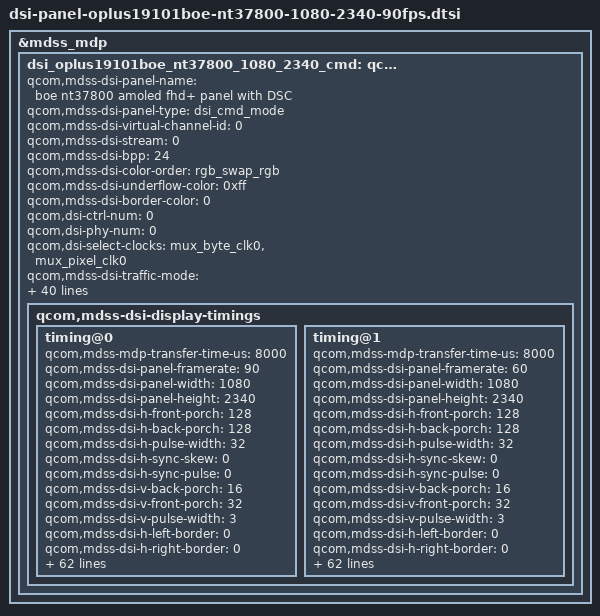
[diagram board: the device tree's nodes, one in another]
&mdss_mdp {
	dsi_oplus19101boe_nt37800_1080_2340_cmd: qcom,mdss_dsi_oplus19101boe_nt37800_1080_2340_cmd {
		qcom,mdss-dsi-panel-name =
		  "boe nt37800 amoled fhd+ panel with DSC";
		qcom,mdss-dsi-panel-type = "dsi_cmd_mode";
		qcom,mdss-dsi-virtual-channel-id = <0>;
		qcom,mdss-dsi-stream = <0>;
		qcom,mdss-dsi-bpp = <24>;
		qcom,mdss-dsi-color-order = "rgb_swap_rgb";
		qcom,mdss-dsi-underflow-color = <0xff>;
		qcom,mdss-dsi-border-color = <0>;

		qcom,dsi-ctrl-num = <0>;
		qcom,dsi-phy-num = <0>;
		qcom,dsi-select-clocks = "src_byte_clk0", "src_pixel_clk0";

		qcom,mdss-dsi-traffic-mode = "non_burst_sync_event";
		qcom,mdss-dsi-lane-map = "lane_map_0123";
		qcom,mdss-dsi-bllp-eof-power-mode;
		qcom,mdss-dsi-bllp-power-mode;
		qcom,mdss-dsi-lane-0-state;
		qcom,mdss-dsi-lane-1-state;
		qcom,mdss-dsi-lane-2-state;
		qcom,mdss-dsi-lane-3-state;
		qcom,mdss-dsi-dma-trigger = "trigger_sw";
		qcom,mdss-dsi-mdp-trigger = "none";
		qcom,mdss-dsi-reset-sequence = <1 10>, <0 10>, <1 10>;
		qcom,mdss-dsi-te-pin-select = <1>;
		qcom,mdss-dsi-wr-mem-start = <0x2c>;
		qcom,mdss-dsi-wr-mem-continue = <0x3c>;
		qcom,mdss-dsi-te-dcs-command = <1>;
		qcom,mdss-dsi-te-check-enable;
		qcom,mdss-dsi-te-using-te-pin;
		qcom,mdss-dsi-lp11-init;
		qcom,mdss-dsi-panel-hdr-enabled;
		qcom,mdss-dsi-panel-hdr-color-primaries = <15000 15500 34000
			16000 13250 34500 7500 3000>;
		qcom,mdss-dsi-panel-peak-brightness = <4300000>;
		qcom,mdss-dsi-panel-blackness-level = <1023>;
		qcom,mdss-brightness-max-level = <1023>;

		qcom,mdss-dsi-display-timings {
			timing@0{
				//qcom,mdss-dsi-panel-clockrate = <1107000000>;
				qcom,mdss-mdp-transfer-time-us = <8000>;
				qcom,mdss-dsi-panel-framerate = <90>; /* 90 FPS */
				qcom,mdss-dsi-panel-width = <1080>;
				qcom,mdss-dsi-panel-height = <2340>;
				qcom,mdss-dsi-h-front-porch = <128>;
				qcom,mdss-dsi-h-back-porch = <128>;
				qcom,mdss-dsi-h-pulse-width = <32>;
				qcom,mdss-dsi-h-sync-skew = <0>;
				qcom,mdss-dsi-h-sync-pulse = <0>;
				qcom,mdss-dsi-v-back-porch = <16>;
				qcom,mdss-dsi-v-front-porch = <32>;
				qcom,mdss-dsi-v-pulse-width = <3>;
				qcom,mdss-dsi-h-left-border = <0>;
				qcom,mdss-dsi-h-right-border = <0>;
				qcom,mdss-dsi-v-top-border = <0>;
				qcom,mdss-dsi-v-bottom-border = <0>;
				qcom,mdss-dsi-panel-jitter = <0xa 0x1>;
				qcom,mdss-dsi-timing-switch-command = [
					39 01 00 00 00 00 06 F0 55 AA 52 08 00
					15 01 00 00 00 00 02 6F 0E
					15 01 00 00 00 00 02 BA 08
					15 01 00 00 00 00 02 6F 03
					39 01 00 00 00 00 04 C0 80 00 00
				];
				qcom,mdss-dsi-on-command = [
					39 01 00 00 00 00 06 F0 55 AA 52 00 00
					/* 90 FPS Setting */
					39 01 00 00 00 00 06 F0 55 AA 52 08 00 /* 90 FPS */
					15 01 00 00 00 00 02 6F 0E
					15 01 00 00 00 00 02 BA 08
					15 01 00 00 00 00 02 6F 03
					39 01 00 00 00 00 04 C0 80 00 00 /* 90 FPS */
					05 01 00 00 00 00 01 35
					39 01 00 00 00 00 05 3B 00 10 00 04
					15 01 00 00 00 00 02 53 20
					39 01 00 00 00 00 05 51 03 FF 0F FF
					39 01 00 00 00 00 05 2A 00 00 04 37
					39 01 00 00 00 00 05 2B 00 00 09 23
					/* DSC Setting */
					39 01 00 00 00 00 13 93 89 28 00 14 02 00 02 0E 01 E8 00 07 05 0E 05 16 10 F0
					15 01 00 00 00 00 02 90 01
					15 01 00 00 00 00 02 03 11
					05 01 00 00 00 00 01 2C
					/* Sleep Out(11h) */
					05 01 00 00 78 00 01 11
					];
				qcom,mdss-dsi-post-on-backlight = [
					05 01 00 00 00 00 01 29
					];
				qcom,mdss-dsi-off-command = [
					05 01 00 00 0A 00 01 28
					05 01 00 00 78 00 01 10];
				qcom,mdss-dsi-lp1-command = [    /* AOD ON */
					05 01 00 00 00 00 01 39
					15 01 00 00 00 00 02 65 01
					05 01 00 00 00 00 01 2C
					];
				qcom,mdss-dsi-nolp-command = [    /* AOD OFF */
					15 01 00 00 00 00 02 65 00
					05 01 00 00 00 00 01 38
					05 01 00 00 00 00 01 2C
					];
				qcom,mdss-dsi-aod-hbm-on-command = [  /*AOD->HBM ON PANEL FINGERPRINT OFF*/
					39 01 00 00 00 00 03 F0 5A 5A
					39 01 00 00 00 00 03 51 03 FF
					15 01 00 00 00 00 02 53 E0
					/* HBM 670 ON */
					39 01 00 00 00 00 03 BD 00 00
					39 01 00 00 00 00 03 F0 A5 A5];
				qcom,mdss-dsi-aod-hbm-off-command = [  /*AOD->HBM OFF PANEL FINGERPRINT OFF*/
					39 01 00 00 00 00 03 F0 5A 5A
					39 01 00 00 00 00 03 BD 00 02
					39 01 00 00 00 00 03 F0 A5 A5
					39 01 00 00 00 00 03 51 00 01
					15 01 00 00 00 00 02 53 22];
				qcom,mdss-dsi-hbm-on-command = [
					39 01 00 00 00 00 03 51 0F FF
					];
				qcom,mdss-dsi-hbm-off-command = [
					39 01 00 00 00 00 03 51 06 40
					];
				qcom,mdss-dsi-normal-hbm-on-command = [
					39 01 00 00 00 00 03 51 0F FF
					];
				qcom,mdss-dsi-aod-high-mode-command = [
					/* AOD 50nit */
					39 01 00 00 00 00 03 F0 5A 5A
					15 01 00 00 00 00 02 53 22
					15 01 00 00 00 00 02 B0 A5
					15 01 00 00 00 00 02 C7 00
					39 01 00 00 00 00 03 F0 A5 A5];
				qcom,mdss-dsi-aod-low-mode-command = [
					/* AOD 10nit */
					39 01 00 00 00 00 03 F0 5A 5A
					15 01 00 00 00 00 02 53 23
					15 01 00 00 00 00 02 B0 A5
					15 01 00 00 00 00 02 C7 00
					39 01 00 00 00 00 03 F0 A5 A5];
				qcom,mdss-dsi-seed-1-command = [
					];
				qcom,mdss-dsi-seed-2-command = [
					];
				qcom,mdss-dsi-spr-0-command = [
					39 01 00 00 00 00 06 F0 55 AA 52 08 07
					39 01 00 00 00 00 07 B0 A4 40 70 60 00 00
					39 01 00 00 00 00 18 B1 08 18 00 18 08 00 00 00 00 00 00 00 00 00 00 00 00 00 00 00 00 00 00
					39 01 00 00 00 00 B5 B2 20 20 20 20 20 20 20 20 20 20 20 20 20 20 20 20 20 20 20 20 20 20 20 20 20 20 20 20 20 20 20 20 20 20 20 20 20 20 20 20 20 20 20 20 20 20 20 20 20 20 20 20 20 20 32 32 32 32 32 32 32 32 32 00 00 00 00 00 00 00 00 00 32 32 32 32 32 32 32 32 32 00 00 00 00 00 00 00 00 00 32 32 32 32 32 32 32 32 32 00 00 00 00 00 00 00 00 00 32 32 32 32 32 32 32 32 32 00 00 00 00 00 00 00 00 00 32 32 32 32 32 32 32 32 32 00 00 00 00 00 00 00 00 00 32 32 32 32 32 32 32 32 32 00 00 00 00 00 00 00 00 00 00 00 20 00 20 00 00 00 00 00 32 00 00 00 32 00 00 00
					39 01 00 00 00 00 5B B3 00 00 00 00 00 00 00 00 00 00 00 00 00 00 00 00 00 00 00 00 00 00 00 00 00 00 00 00 00 00 00 00 00 00 00 00 00 00 00 00 00 00 00 00 00 00 00 00 00 00 00 00 00 00 00 00 00 00 00 00 00 00 00 00 00 00 00 00 00 00 00 00 00 00 00 00 00 00 00 00 00 00 00 00 00 00 00 00 00 00
					39 01 00 00 00 00 1B B4 C0 00 00 00 00 00 00 00 00 00 00 00 00 00 80 80 80 80 40 80 80 80 80 80 40 80
					39 01 00 00 00 00 49 B5 00 00 00 00 00 00 00 00 00 00 00 00 00 00 00 00 00 00 00 00 00 00 04 00 00 00 00 00 00 00 00 00 00 00 00 00 00 00 00 00 00 00 00 00 00 00 00 00 00 00 00 00 00 00 00 00 00 00 00 00 00 00 00 00 00 00 00 00 00 00 00 00
					39 01 00 00 00 00 25 B6 00 00 00 00 00 00 00 00 00 00 00 00 00 00 00 00 00 00 00 00 00 00 00 00 E0 00 E0 00 00 00 E0 00 E0 00 00 00
					39 01 00 00 00 00 50 B7 24 84 00 08 01 08 01 00 00 00 00 00 00 00 00 00 00 00 00 00 00 00 00 00 00 00 00 00 00 00 00 00 00 00 00 00 00 00 00 00 00 00 00 FD 58 0E A5 78 2A 1A 77 FE CF 7E 0D E5 B2 B7 87 CC 14 80 80 80 80 80 80 80 80 80 80 80 80 80 80 80 80 80 80
					39 01 00 00 00 00 58 B8 00 00 00 00 00 00 00 00 00 00 00 00 00 00 00 00 00 00 00 02 02 00 00 00 00 00 00 00 00 00 00 00 00 00 00 00 00 00 00 00 00 00 00 00 00 00 00 00 00 00 00 00 00 00 00 00 00 00 00 00 00 00 00 00 00 00 00 00 00 00 00 00 00 00 00 00 00 00 00 00 00 00 00 00 00 00 00
					39 01 00 00 00 00 C1 B9 00 00 00 00 00 00 00 00 00 00 00 00 00 00 00 00 00 00 00 00 00 00 00 00 00 00 00 00 00 00 00 00 00 00 00 00 00 00 00 00 00 00 00 00 00 00 00 00 00 00 00 00 00 00 00 00 00 00 00 00 00 00 00 00 00 00 00 00 00 00 00 00 00 00 00 00 00 00 00 00 00 00 00 00 00 00 00 00 00 00 00 00 00 00 00 00 00 00 00 00 00 00 00 00 00 00 00 00 00 00 00 00 00 00 00 00 00 00 00 00 00 00 00 00 00 00 00 00 00 00 00 00 00 00 00 00 00 00 00 00 00 00 00 00 00 00 00 00 00 00 00 00 00 00 00 00 00 00 00 00 00 00 00 00 00 00 00 00 00 00 00 00 00 00 00 00 00 00 00 00 00 00 00 00 00 00 00 00 00 00 00 00
					39 01 00 00 00 00 20 BA 00 00 00 00 00 00 00 00 00 00 00 00 00 00 00 00 00 00 00 00 00 00 00 00 00 00 00 00 00 00 00
					39 01 00 00 00 00 88 BB 00 00 00 00 00 00 00 00 00 00 00 00 00 00 00 00 00 00 00 00 00 00 00 00 00 00 00 00 00 00 00 00 00 00 00 00 00 00 00 00 00 00 00 00 00 00 00 00 00 00 00 00 00 00 00 00 00 00 00 00 00 00 00 00 00 00 00 00 00 00 00 00 00 00 00 00 00 00 00 00 00 00 00 00 00 00 00 00 00 00 00 00 00 00 00 00 00 00 00 00 00 00 00 00 00 00 00 00 00 00 00 00 00 00 00 00 00 00 00 00 00 00 00 00 00 00 00 00 00 00 00 00 00 00 00
					39 01 00 00 00 00 14 BC 00 00 00 00 00 00 00 00 00 00 00 00 00 00 00 00 00 00 00
					39 01 00 00 00 00 0D BD 00 00 00 00 00 00 00 00 00 00 00 00
					];
				qcom,mdss-dsi-spr-1-command = [
					39 01 00 00 00 00 06 F0 55 AA 52 08 07
					39 01 00 00 00 00 07 B0 A4 40 70 60 00 00
					39 01 00 00 00 00 03 B7 80 90
					39 01 00 00 00 00 02 6F 43
					39 01 00 00 00 00 04 B7 80 70 80
					39 01 00 00 00 00 02 6F 46
					39 01 00 00 00 00 04 B7 80 70 80
					39 01 00 00 00 00 18 B1 0C 1C 00 1C 0C 00 00 00 00 00 00 00 00 00 00 00 00 00 00 00 00 00 00
					39 01 00 00 00 00 B5 B2 22 22 22 22 22 22 22 22 22 22 22 22 22 22 22 22 22 22 00 00 00 00 00 00 00 00 00 22 22 22 22 22 22 22 22 22 22 22 22 22 22 22 22 22 22 00 00 00 00 00 00 00 00 00 3A 3A 3A 3A 3A 3A 3A 3A 3A 05 05 05 05 05 05 05 05 05 3A 3A 3A 3A 3A 3A 3A 3A 3A 05 05 05 05 05 05 05 05 05 00 00 00 00 00 00 00 00 00 00 00 00 00 00 00 00 00 00 3A 3A 3A 3A 3A 3A 3A 3A 3A 05 05 05 05 05 05 05 05 05 3A 3A 3A 3A 3A 3A 3A 3A 3A 05 05 05 05 05 05 05 05 05 00 00 00 00 00 00 00 00 00 00 00 00 00 00 00 00 00 00 00 00 00 00 00 00 00 00 00 00 00 00 00 00 00 00 00 00
					39 01 00 00 00 00 5B B3 00 00 00 00 00 00 00 00 00 00 00 00 00 00 00 00 00 00 00 00 00 00 00 00 00 00 00 00 00 00 00 00 00 00 00 00 00 00 00 00 00 00 00 00 00 00 00 00 00 00 00 00 00 00 00 00 00 00 00 00 00 00 00 00 00 00 00 00 00 00 00 00 00 00 00 00 00 00 00 00 00 00 00 00 00 00 00 00 00 00
					39 01 00 00 00 00 1B B4 C0 00 00 00 00 00 00 00 00 00 00 00 00 00 80 68 80 80 60 80 80 60 80 80 A0 80
					39 01 00 00 00 00 49 B5 00 00 00 00 00 00 00 00 00 00 00 00 00 00 00 00 00 00 00 00 00 00 04 00 00 00 00 00 00 00 00 00 00 00 00 00 00 00 00 00 00 00 00 00 00 00 00 00 00 00 00 00 00 00 00 00 00 00 00 00 00 00 00 00 00 00 00 00 00 00 00 00
					39 01 00 00 00 00 25 B6 00 00 00 00 00 00 00 00 00 00 00 00 00 00 00 00 00 00 00 00 00 00 00 00 E0 00 E0 00 00 00 E0 00 E0 00 00 00
					39 01 00 00 00 00 58 B8 00 00 00 00 00 00 00 00 00 00 00 00 00 00 00 00 00 00 00 02 02 00 00 00 00 00 00 00 00 00 00 00 00 00 00 00 00 00 00 00 00 00 00 00 00 00 00 00 00 00 00 00 00 00 00 00 00 00 00 00 00 00 00 00 00 00 00 00 00 00 00 00 00 00 00 00 00 00 00 00 00 00 00 00 00 00 00
					39 01 00 00 00 00 C1 B9 00 00 00 00 00 00 00 00 00 00 00 00 00 00 00 00 00 00 00 00 00 00 00 00 00 00 00 00 00 00 00 00 00 00 00 00 00 00 00 00 00 00 00 00 00 00 00 00 00 00 00 00 00 00 00 00 00 00 00 00 00 00 00 00 00 00 00 00 00 00 00 00 00 00 00 00 00 00 00 00 00 00 00 00 00 00 00 00 00 00 00 00 00 00 00 00 00 00 00 00 00 00 00 00 00 00 00 00 00 00 00 00 00 00 00 00 00 00 00 00 00 00 00 00 00 00 00 00 00 00 00 00 00 00 00 00 00 00 00 00 00 00 00 00 00 00 00 00 00 00 00 00 00 00 00 00 00 00 00 00 00 00 00 00 00 00 00 00 00 00 00 00 00 00 00 00 00 00 00 00 00 00 00 00 00 00 00 00 00 00 00 00
					39 01 00 00 00 00 20 BA 00 00 00 00 00 00 00 00 00 00 00 00 00 00 00 00 00 00 00 00 00 00 00 00 00 00 00 00 00 00 00
					39 01 00 00 00 00 88 BB 00 00 00 00 00 00 00 00 00 00 00 00 00 00 00 00 00 00 00 00 00 00 00 00 00 00 00 00 00 00 00 00 00 00 00 00 00 00 00 00 00 00 00 00 00 00 00 00 00 00 00 00 00 00 00 00 00 00 00 00 00 00 00 00 00 00 00 00 00 00 00 00 00 00 00 00 00 00 00 00 00 00 00 00 00 00 00 00 00 00 00 00 00 00 00 00 00 00 00 00 00 00 00 00 00 00 00 00 00 00 00 00 00 00 00 00 00 00 00 00 00 00 00 00 00 00 00 00 00 00 00 00 00 00 00
					39 01 00 00 00 00 14 BC 00 00 00 00 00 00 00 00 00 00 00 00 00 00 00 00 00 00 00
					39 01 00 00 00 00 0D BD 00 00 00 00 00 00 00 00 00 00 00 00
					];
				qcom,mdss-dsi-spr-2-command = [
					39 01 00 00 00 00 06 F0 55 AA 52 08 07
					39 01 00 00 00 00 07 B0 A4 40 70 60 00 00
					39 01 00 00 00 00 18 B1 08 18 00 18 08 00 00 00 00 00 00 00 00 00 00 00 00 00 00 00 00 00 00
					39 01 00 00 00 00 B5 B2 20 20 20 20 20 20 20 20 20 20 20 20 20 20 20 20 20 20 20 20 20 20 20 20 20 20 20 20 20 20 20 20 20 20 20 20 20 20 20 20 20 20 20 20 20 20 20 20 20 20 20 20 20 20 03 03 03 03 03 03 03 03 03 00 00 00 00 00 00 00 00 00 03 03 03 03 03 03 03 03 03 00 00 00 00 00 00 00 00 00 03 03 03 03 03 03 03 03 03 00 00 00 00 00 00 00 00 00 03 03 03 03 03 03 03 03 03 00 00 00 00 00 00 00 00 00 03 03 03 03 03 03 03 03 03 00 00 00 00 00 00 00 00 00 03 03 03 03 03 03 03 03 03 00 00 00 00 00 00 00 00 00 00 00 20 00 20 00 00 00 00 00 32 00 00 00 32 00 00 00
					39 01 00 00 00 00 5B B3 00 00 00 00 00 00 00 00 00 00 00 00 00 00 00 00 00 00 00 00 00 00 00 00 00 00 00 00 00 00 00 00 00 00 00 00 00 00 00 00 00 00 00 00 00 00 00 00 00 00 00 00 00 00 00 00 00 00 00 00 00 00 00 00 00 00 00 00 00 00 00 00 00 00 00 00 00 00 00 00 00 00 00 00 00 00 00 00 00 00
					39 01 00 00 00 00 1B B4 C0 00 00 00 00 00 00 00 00 00 00 00 00 00 80 80 80 80 40 80 80 80 80 80 40 80
					39 01 00 00 00 00 49 B5 00 00 00 00 00 00 00 00 00 00 00 00 00 00 00 00 00 00 00 00 00 00 04 00 00 00 00 00 00 00 00 00 00 00 00 00 00 00 00 00 00 00 00 00 00 00 00 00 00 00 00 00 00 00 00 00 00 00 00 00 00 00 00 00 00 00 00 00 00 00 00 00
					39 01 00 00 00 00 25 B6 00 00 00 00 00 00 00 00 00 00 00 00 00 00 00 00 00 00 00 00 00 00 00 00 E0 00 E0 00 00 00 E0 00 E0 00 00 00
					39 01 00 00 00 00 50 B7 24 84 00 08 01 08 01 00 00 00 00 00 00 00 00 00 00 00 00 00 00 00 00 00 00 00 00 00 00 00 00 00 00 00 00 00 00 00 00 00 00 00 00 FD 58 0E A5 78 2A 1A 77 FE CF 7E 0D E5 B2 B7 87 CC 14 80 80 80 80 80 80 80 80 80 80 80 80 80 80 80 80 80 80
					39 01 00 00 00 00 58 B8 00 00 00 00 00 00 00 00 00 00 00 00 00 00 00 00 00 00 00 02 02 00 00 00 00 00 00 00 00 00 00 00 00 00 00 00 00 00 00 00 00 00 00 00 00 00 00 00 00 00 00 00 00 00 00 00 00 00 00 00 00 00 00 00 00 00 00 00 00 00 00 00 00 00 00 00 00 00 00 00 00 00 00 00 00 00 00
					39 01 00 00 00 00 C1 B9 00 00 00 00 00 00 00 00 00 00 00 00 00 00 00 00 00 00 00 00 00 00 00 00 00 00 00 00 00 00 00 00 00 00 00 00 00 00 00 00 00 00 00 00 00 00 00 00 00 00 00 00 00 00 00 00 00 00 00 00 00 00 00 00 00 00 00 00 00 00 00 00 00 00 00 00 00 00 00 00 00 00 00 00 00 00 00 00 00 00 00 00 00 00 00 00 00 00 00 00 00 00 00 00 00 00 00 00 00 00 00 00 00 00 00 00 00 00 00 00 00 00 00 00 00 00 00 00 00 00 00 00 00 00 00 00 00 00 00 00 00 00 00 00 00 00 00 00 00 00 00 00 00 00 00 00 00 00 00 00 00 00 00 00 00 00 00 00 00 00 00 00 00 00 00 00 00 00 00 00 00 00 00 00 00 00 00 00 00 00 00 00
					39 01 00 00 00 00 20 BA 00 00 00 00 00 00 00 00 00 00 00 00 00 00 00 00 00 00 00 00 00 00 00 00 00 00 00 00 00 00 00
					39 01 00 00 00 00 88 BB 00 00 00 00 00 00 00 00 00 00 00 00 00 00 00 00 00 00 00 00 00 00 00 00 00 00 00 00 00 00 00 00 00 00 00 00 00 00 00 00 00 00 00 00 00 00 00 00 00 00 00 00 00 00 00 00 00 00 00 00 00 00 00 00 00 00 00 00 00 00 00 00 00 00 00 00 00 00 00 00 00 00 00 00 00 00 00 00 00 00 00 00 00 00 00 00 00 00 00 00 00 00 00 00 00 00 00 00 00 00 00 00 00 00 00 00 00 00 00 00 00 00 00 00 00 00 00 00 00 00 00 00 00 00 00
					39 01 00 00 00 00 14 BC 00 00 00 00 00 00 00 00 00 00 00 00 00 00 00 00 00 00 00
					39 01 00 00 00 00 0D BD 00 00 00 00 00 00 00 00 00 00 00 00
					];
				qcom,mdss-dsi-lp1-command-state = "dsi_hs_mode";
				qcom,mdss-dsi-nolp-command-state = "dsi_hs_mode";
				qcom,mdss-dsi-post-on-backlight-state = "dsi_hs_mode";
				qcom,mdss-dsi-on-command-state = "dsi_lp_mode";
				qcom,mdss-dsi-off-command-state = "dsi_hs_mode";
				qcom,mdss-dsi-normal-hbm-on-command-state = "dsi_hs_mode";
				qcom,mdss-dsi-aod-high-mode-command-state = "dsi_hs_mode";
				qcom,mdss-dsi-aod-low-mode-command-state = "dsi_hs_mode";
				qcom,mdss-dsi-timing-switch-command-state = "dsi_lp_mode";
				qcom,compression-mode = "dsc";
				qcom,mdss-dsc-slice-height = <20>;
				qcom,mdss-dsc-slice-width = <540>;
				qcom,mdss-dsc-slice-per-pkt = <2>;
				qcom,mdss-dsc-bit-per-component = <8>;
				qcom,mdss-dsc-bit-per-pixel = <8>;
				qcom,mdss-dsc-block-prediction-enable;
			};
			
			timing@1{
				//qcom,mdss-dsi-panel-clockrate = <1107000000>;
				qcom,mdss-mdp-transfer-time-us = <8000>;
				qcom,mdss-dsi-panel-framerate = <60>; /* 60 FPS */
				qcom,mdss-dsi-panel-width = <1080>;
				qcom,mdss-dsi-panel-height = <2340>;
				qcom,mdss-dsi-h-front-porch = <128>;
				qcom,mdss-dsi-h-back-porch = <128>;
				qcom,mdss-dsi-h-pulse-width = <32>;
				qcom,mdss-dsi-h-sync-skew = <0>;
				qcom,mdss-dsi-h-sync-pulse = <0>;
				qcom,mdss-dsi-v-back-porch = <16>;
				qcom,mdss-dsi-v-front-porch = <32>;
				qcom,mdss-dsi-v-pulse-width = <3>;
				qcom,mdss-dsi-h-left-border = <0>;
				qcom,mdss-dsi-h-right-border = <0>;
				qcom,mdss-dsi-v-top-border = <0>;
				qcom,mdss-dsi-v-bottom-border = <0>;
				qcom,mdss-dsi-panel-jitter = <0xa 0x1>;
				qcom,mdss-dsi-timing-switch-command = [
					39 01 00 00 00 00 06 F0 55 AA 52 08 00 /* 60 FPS */
					15 01 00 00 00 00 02 6F 0E
					15 01 00 00 00 00 02 BA 38
					15 01 00 00 00 00 02 6F 03
					39 01 00 00 00 00 04 C0 80 00 00 /* 60 FPS */
				];
				qcom,mdss-dsi-on-command = [
					39 01 00 00 00 00 06 F0 55 AA 52 00 00
					39 01 00 00 00 00 06 F0 55 AA 52 08 00 /* 60 FPS */
					15 01 00 00 00 00 02 6F 0E
					15 01 00 00 00 00 02 BA 38
					15 01 00 00 00 00 02 6F 03
					39 01 00 00 00 00 04 C0 80 00 00 /* 60 FPS */
					05 01 00 00 00 00 01 35
					39 01 00 00 00 00 05 3B 00 10 00 04
					15 01 00 00 00 00 02 53 20
					39 01 00 00 00 00 05 51 03 FF 0F FF
					39 01 00 00 00 00 05 2A 00 00 04 37
					39 01 00 00 00 00 05 2B 00 00 09 23
					/* DSC Setting */
					39 01 00 00 00 00 13 93 89 28 00 14 02 00 02 0E 01 E8 00 07 05 0E 05 16 10 F0
					15 01 00 00 00 00 02 90 01
					15 01 00 00 00 00 02 03 11
					05 01 00 00 00 00 01 2C
					/* Sleep Out(11h) */
					05 01 00 00 78 00 01 11
					];
				qcom,mdss-dsi-post-on-backlight = [
					05 01 00 00 00 00 01 29
					];
				qcom,mdss-dsi-off-command = [
					05 01 00 00 0A 00 01 28
					05 01 00 00 78 00 01 10];
				qcom,mdss-dsi-lp1-command = [    /* AOD ON */
					05 01 00 00 00 00 01 39
					15 01 00 00 00 00 02 65 01
					05 01 00 00 00 00 01 2C
					];
				qcom,mdss-dsi-nolp-command = [    /* AOD OFF */
					15 01 00 00 00 00 02 65 00
					05 01 00 00 00 00 01 38
					05 01 00 00 00 00 01 2C
					];
				qcom,mdss-dsi-aod-hbm-on-command = [  /*AOD->HBM ON PANEL FINGERPRINT OFF*/
					39 01 00 00 00 00 03 F0 5A 5A
					39 01 00 00 00 00 03 51 03 FF
					15 01 00 00 00 00 02 53 E0
					/* HBM 670 ON */
					39 01 00 00 00 00 03 BD 00 00
					39 01 00 00 00 00 03 F0 A5 A5];
				qcom,mdss-dsi-aod-hbm-off-command = [  /*AOD->HBM OFF PANEL FINGERPRINT OFF*/
					39 01 00 00 00 00 03 F0 5A 5A
					39 01 00 00 00 00 03 BD 00 02
					39 01 00 00 00 00 03 F0 A5 A5
					39 01 00 00 00 00 03 51 00 01
					15 01 00 00 00 00 02 53 22];
				qcom,mdss-dsi-hbm-on-command = [
					39 01 00 00 00 00 03 51 0F FF
					];
				qcom,mdss-dsi-hbm-off-command = [
					39 01 00 00 00 00 03 51 06 40
					];
				qcom,mdss-dsi-normal-hbm-on-command = [
					39 01 00 00 00 00 03 51 0F FF
					];
				qcom,mdss-dsi-aod-high-mode-command = [
					/* AOD 50nit */
					39 01 00 00 00 00 03 F0 5A 5A
					15 01 00 00 00 00 02 53 22
					15 01 00 00 00 00 02 B0 A5
					15 01 00 00 00 00 02 C7 00
					39 01 00 00 00 00 03 F0 A5 A5];
				qcom,mdss-dsi-aod-low-mode-command = [
					/* AOD 10nit */
					39 01 00 00 00 00 03 F0 5A 5A
					15 01 00 00 00 00 02 53 23
					15 01 00 00 00 00 02 B0 A5
					15 01 00 00 00 00 02 C7 00
					39 01 00 00 00 00 03 F0 A5 A5];
				qcom,mdss-dsi-seed-1-command = [
					];
				qcom,mdss-dsi-seed-2-command = [
					];
				qcom,mdss-dsi-spr-0-command = [
					39 01 00 00 00 00 06 F0 55 AA 52 08 07
					39 01 00 00 00 00 07 B0 A4 40 70 60 00 00
					39 01 00 00 00 00 18 B1 08 18 00 18 08 00 00 00 00 00 00 00 00 00 00 00 00 00 00 00 00 00 00
					39 01 00 00 00 00 B5 B2 20 20 20 20 20 20 20 20 20 20 20 20 20 20 20 20 20 20 20 20 20 20 20 20 20 20 20 20 20 20 20 20 20 20 20 20 20 20 20 20 20 20 20 20 20 20 20 20 20 20 20 20 20 20 32 32 32 32 32 32 32 32 32 00 00 00 00 00 00 00 00 00 32 32 32 32 32 32 32 32 32 00 00 00 00 00 00 00 00 00 32 32 32 32 32 32 32 32 32 00 00 00 00 00 00 00 00 00 32 32 32 32 32 32 32 32 32 00 00 00 00 00 00 00 00 00 32 32 32 32 32 32 32 32 32 00 00 00 00 00 00 00 00 00 32 32 32 32 32 32 32 32 32 00 00 00 00 00 00 00 00 00 00 00 20 00 20 00 00 00 00 00 32 00 00 00 32 00 00 00
					39 01 00 00 00 00 5B B3 00 00 00 00 00 00 00 00 00 00 00 00 00 00 00 00 00 00 00 00 00 00 00 00 00 00 00 00 00 00 00 00 00 00 00 00 00 00 00 00 00 00 00 00 00 00 00 00 00 00 00 00 00 00 00 00 00 00 00 00 00 00 00 00 00 00 00 00 00 00 00 00 00 00 00 00 00 00 00 00 00 00 00 00 00 00 00 00 00 00
					39 01 00 00 00 00 1B B4 C0 00 00 00 00 00 00 00 00 00 00 00 00 00 80 80 80 80 40 80 80 80 80 80 40 80
					39 01 00 00 00 00 49 B5 00 00 00 00 00 00 00 00 00 00 00 00 00 00 00 00 00 00 00 00 00 00 04 00 00 00 00 00 00 00 00 00 00 00 00 00 00 00 00 00 00 00 00 00 00 00 00 00 00 00 00 00 00 00 00 00 00 00 00 00 00 00 00 00 00 00 00 00 00 00 00 00
					39 01 00 00 00 00 25 B6 00 00 00 00 00 00 00 00 00 00 00 00 00 00 00 00 00 00 00 00 00 00 00 00 E0 00 E0 00 00 00 E0 00 E0 00 00 00
					39 01 00 00 00 00 50 B7 24 84 00 08 01 08 01 00 00 00 00 00 00 00 00 00 00 00 00 00 00 00 00 00 00 00 00 00 00 00 00 00 00 00 00 00 00 00 00 00 00 00 00 FD 58 0E A5 78 2A 1A 77 FE CF 7E 0D E5 B2 B7 87 CC 14 80 80 80 80 80 80 80 80 80 80 80 80 80 80 80 80 80 80
					39 01 00 00 00 00 58 B8 00 00 00 00 00 00 00 00 00 00 00 00 00 00 00 00 00 00 00 02 02 00 00 00 00 00 00 00 00 00 00 00 00 00 00 00 00 00 00 00 00 00 00 00 00 00 00 00 00 00 00 00 00 00 00 00 00 00 00 00 00 00 00 00 00 00 00 00 00 00 00 00 00 00 00 00 00 00 00 00 00 00 00 00 00 00 00
					39 01 00 00 00 00 C1 B9 00 00 00 00 00 00 00 00 00 00 00 00 00 00 00 00 00 00 00 00 00 00 00 00 00 00 00 00 00 00 00 00 00 00 00 00 00 00 00 00 00 00 00 00 00 00 00 00 00 00 00 00 00 00 00 00 00 00 00 00 00 00 00 00 00 00 00 00 00 00 00 00 00 00 00 00 00 00 00 00 00 00 00 00 00 00 00 00 00 00 00 00 00 00 00 00 00 00 00 00 00 00 00 00 00 00 00 00 00 00 00 00 00 00 00 00 00 00 00 00 00 00 00 00 00 00 00 00 00 00 00 00 00 00 00 00 00 00 00 00 00 00 00 00 00 00 00 00 00 00 00 00 00 00 00 00 00 00 00 00 00 00 00 00 00 00 00 00 00 00 00 00 00 00 00 00 00 00 00 00 00 00 00 00 00 00 00 00 00 00 00 00
					39 01 00 00 00 00 20 BA 00 00 00 00 00 00 00 00 00 00 00 00 00 00 00 00 00 00 00 00 00 00 00 00 00 00 00 00 00 00 00
					39 01 00 00 00 00 88 BB 00 00 00 00 00 00 00 00 00 00 00 00 00 00 00 00 00 00 00 00 00 00 00 00 00 00 00 00 00 00 00 00 00 00 00 00 00 00 00 00 00 00 00 00 00 00 00 00 00 00 00 00 00 00 00 00 00 00 00 00 00 00 00 00 00 00 00 00 00 00 00 00 00 00 00 00 00 00 00 00 00 00 00 00 00 00 00 00 00 00 00 00 00 00 00 00 00 00 00 00 00 00 00 00 00 00 00 00 00 00 00 00 00 00 00 00 00 00 00 00 00 00 00 00 00 00 00 00 00 00 00 00 00 00 00
					39 01 00 00 00 00 14 BC 00 00 00 00 00 00 00 00 00 00 00 00 00 00 00 00 00 00 00
					39 01 00 00 00 00 0D BD 00 00 00 00 00 00 00 00 00 00 00 00
					];
				qcom,mdss-dsi-spr-1-command = [
					39 01 00 00 00 00 06 F0 55 AA 52 08 07
					39 01 00 00 00 00 07 B0 A4 40 70 60 00 00
					39 01 00 00 00 00 03 B7 80 90
					39 01 00 00 00 00 02 6F 43
					39 01 00 00 00 00 04 B7 80 70 80
					39 01 00 00 00 00 02 6F 46
					39 01 00 00 00 00 04 B7 80 70 80
					39 01 00 00 00 00 18 B1 0C 1C 00 1C 0C 00 00 00 00 00 00 00 00 00 00 00 00 00 00 00 00 00 00
					39 01 00 00 00 00 B5 B2 22 22 22 22 22 22 22 22 22 22 22 22 22 22 22 22 22 22 00 00 00 00 00 00 00 00 00 22 22 22 22 22 22 22 22 22 22 22 22 22 22 22 22 22 22 00 00 00 00 00 00 00 00 00 3A 3A 3A 3A 3A 3A 3A 3A 3A 05 05 05 05 05 05 05 05 05 3A 3A 3A 3A 3A 3A 3A 3A 3A 05 05 05 05 05 05 05 05 05 00 00 00 00 00 00 00 00 00 00 00 00 00 00 00 00 00 00 3A 3A 3A 3A 3A 3A 3A 3A 3A 05 05 05 05 05 05 05 05 05 3A 3A 3A 3A 3A 3A 3A 3A 3A 05 05 05 05 05 05 05 05 05 00 00 00 00 00 00 00 00 00 00 00 00 00 00 00 00 00 00 00 00 00 00 00 00 00 00 00 00 00 00 00 00 00 00 00 00
					39 01 00 00 00 00 5B B3 00 00 00 00 00 00 00 00 00 00 00 00 00 00 00 00 00 00 00 00 00 00 00 00 00 00 00 00 00 00 00 00 00 00 00 00 00 00 00 00 00 00 00 00 00 00 00 00 00 00 00 00 00 00 00 00 00 00 00 00 00 00 00 00 00 00 00 00 00 00 00 00 00 00 00 00 00 00 00 00 00 00 00 00 00 00 00 00 00 00
					39 01 00 00 00 00 1B B4 C0 00 00 00 00 00 00 00 00 00 00 00 00 00 80 68 80 80 60 80 80 60 80 80 A0 80
					39 01 00 00 00 00 49 B5 00 00 00 00 00 00 00 00 00 00 00 00 00 00 00 00 00 00 00 00 00 00 04 00 00 00 00 00 00 00 00 00 00 00 00 00 00 00 00 00 00 00 00 00 00 00 00 00 00 00 00 00 00 00 00 00 00 00 00 00 00 00 00 00 00 00 00 00 00 00 00 00
					39 01 00 00 00 00 25 B6 00 00 00 00 00 00 00 00 00 00 00 00 00 00 00 00 00 00 00 00 00 00 00 00 E0 00 E0 00 00 00 E0 00 E0 00 00 00
					39 01 00 00 00 00 58 B8 00 00 00 00 00 00 00 00 00 00 00 00 00 00 00 00 00 00 00 02 02 00 00 00 00 00 00 00 00 00 00 00 00 00 00 00 00 00 00 00 00 00 00 00 00 00 00 00 00 00 00 00 00 00 00 00 00 00 00 00 00 00 00 00 00 00 00 00 00 00 00 00 00 00 00 00 00 00 00 00 00 00 00 00 00 00 00
					39 01 00 00 00 00 C1 B9 00 00 00 00 00 00 00 00 00 00 00 00 00 00 00 00 00 00 00 00 00 00 00 00 00 00 00 00 00 00 00 00 00 00 00 00 00 00 00 00 00 00 00 00 00 00 00 00 00 00 00 00 00 00 00 00 00 00 00 00 00 00 00 00 00 00 00 00 00 00 00 00 00 00 00 00 00 00 00 00 00 00 00 00 00 00 00 00 00 00 00 00 00 00 00 00 00 00 00 00 00 00 00 00 00 00 00 00 00 00 00 00 00 00 00 00 00 00 00 00 00 00 00 00 00 00 00 00 00 00 00 00 00 00 00 00 00 00 00 00 00 00 00 00 00 00 00 00 00 00 00 00 00 00 00 00 00 00 00 00 00 00 00 00 00 00 00 00 00 00 00 00 00 00 00 00 00 00 00 00 00 00 00 00 00 00 00 00 00 00 00 00
					39 01 00 00 00 00 20 BA 00 00 00 00 00 00 00 00 00 00 00 00 00 00 00 00 00 00 00 00 00 00 00 00 00 00 00 00 00 00 00
					39 01 00 00 00 00 88 BB 00 00 00 00 00 00 00 00 00 00 00 00 00 00 00 00 00 00 00 00 00 00 00 00 00 00 00 00 00 00 00 00 00 00 00 00 00 00 00 00 00 00 00 00 00 00 00 00 00 00 00 00 00 00 00 00 00 00 00 00 00 00 00 00 00 00 00 00 00 00 00 00 00 00 00 00 00 00 00 00 00 00 00 00 00 00 00 00 00 00 00 00 00 00 00 00 00 00 00 00 00 00 00 00 00 00 00 00 00 00 00 00 00 00 00 00 00 00 00 00 00 00 00 00 00 00 00 00 00 00 00 00 00 00 00
					39 01 00 00 00 00 14 BC 00 00 00 00 00 00 00 00 00 00 00 00 00 00 00 00 00 00 00
					39 01 00 00 00 00 0D BD 00 00 00 00 00 00 00 00 00 00 00 00
					];
				qcom,mdss-dsi-spr-2-command = [
					39 01 00 00 00 00 06 F0 55 AA 52 08 07
					39 01 00 00 00 00 07 B0 A4 40 70 60 00 00
					39 01 00 00 00 00 18 B1 08 18 00 18 08 00 00 00 00 00 00 00 00 00 00 00 00 00 00 00 00 00 00
					39 01 00 00 00 00 B5 B2 20 20 20 20 20 20 20 20 20 20 20 20 20 20 20 20 20 20 20 20 20 20 20 20 20 20 20 20 20 20 20 20 20 20 20 20 20 20 20 20 20 20 20 20 20 20 20 20 20 20 20 20 20 20 03 03 03 03 03 03 03 03 03 00 00 00 00 00 00 00 00 00 03 03 03 03 03 03 03 03 03 00 00 00 00 00 00 00 00 00 03 03 03 03 03 03 03 03 03 00 00 00 00 00 00 00 00 00 03 03 03 03 03 03 03 03 03 00 00 00 00 00 00 00 00 00 03 03 03 03 03 03 03 03 03 00 00 00 00 00 00 00 00 00 03 03 03 03 03 03 03 03 03 00 00 00 00 00 00 00 00 00 00 00 20 00 20 00 00 00 00 00 32 00 00 00 32 00 00 00
					39 01 00 00 00 00 5B B3 00 00 00 00 00 00 00 00 00 00 00 00 00 00 00 00 00 00 00 00 00 00 00 00 00 00 00 00 00 00 00 00 00 00 00 00 00 00 00 00 00 00 00 00 00 00 00 00 00 00 00 00 00 00 00 00 00 00 00 00 00 00 00 00 00 00 00 00 00 00 00 00 00 00 00 00 00 00 00 00 00 00 00 00 00 00 00 00 00 00
					39 01 00 00 00 00 1B B4 C0 00 00 00 00 00 00 00 00 00 00 00 00 00 80 80 80 80 40 80 80 80 80 80 40 80
					39 01 00 00 00 00 49 B5 00 00 00 00 00 00 00 00 00 00 00 00 00 00 00 00 00 00 00 00 00 00 04 00 00 00 00 00 00 00 00 00 00 00 00 00 00 00 00 00 00 00 00 00 00 00 00 00 00 00 00 00 00 00 00 00 00 00 00 00 00 00 00 00 00 00 00 00 00 00 00 00
					39 01 00 00 00 00 25 B6 00 00 00 00 00 00 00 00 00 00 00 00 00 00 00 00 00 00 00 00 00 00 00 00 E0 00 E0 00 00 00 E0 00 E0 00 00 00
					39 01 00 00 00 00 50 B7 24 84 00 08 01 08 01 00 00 00 00 00 00 00 00 00 00 00 00 00 00 00 00 00 00 00 00 00 00 00 00 00 00 00 00 00 00 00 00 00 00 00 00 FD 58 0E A5 78 2A 1A 77 FE CF 7E 0D E5 B2 B7 87 CC 14 80 80 80 80 80 80 80 80 80 80 80 80 80 80 80 80 80 80
					39 01 00 00 00 00 58 B8 00 00 00 00 00 00 00 00 00 00 00 00 00 00 00 00 00 00 00 02 02 00 00 00 00 00 00 00 00 00 00 00 00 00 00 00 00 00 00 00 00 00 00 00 00 00 00 00 00 00 00 00 00 00 00 00 00 00 00 00 00 00 00 00 00 00 00 00 00 00 00 00 00 00 00 00 00 00 00 00 00 00 00 00 00 00 00
					39 01 00 00 00 00 C1 B9 00 00 00 00 00 00 00 00 00 00 00 00 00 00 00 00 00 00 00 00 00 00 00 00 00 00 00 00 00 00 00 00 00 00 00 00 00 00 00 00 00 00 00 00 00 00 00 00 00 00 00 00 00 00 00 00 00 00 00 00 00 00 00 00 00 00 00 00 00 00 00 00 00 00 00 00 00 00 00 00 00 00 00 00 00 00 00 00 00 00 00 00 00 00 00 00 00 00 00 00 00 00 00 00 00 00 00 00 00 00 00 00 00 00 00 00 00 00 00 00 00 00 00 00 00 00 00 00 00 00 00 00 00 00 00 00 00 00 00 00 00 00 00 00 00 00 00 00 00 00 00 00 00 00 00 00 00 00 00 00 00 00 00 00 00 00 00 00 00 00 00 00 00 00 00 00 00 00 00 00 00 00 00 00 00 00 00 00 00 00 00 00
					39 01 00 00 00 00 20 BA 00 00 00 00 00 00 00 00 00 00 00 00 00 00 00 00 00 00 00 00 00 00 00 00 00 00 00 00 00 00 00
					39 01 00 00 00 00 88 BB 00 00 00 00 00 00 00 00 00 00 00 00 00 00 00 00 00 00 00 00 00 00 00 00 00 00 00 00 00 00 00 00 00 00 00 00 00 00 00 00 00 00 00 00 00 00 00 00 00 00 00 00 00 00 00 00 00 00 00 00 00 00 00 00 00 00 00 00 00 00 00 00 00 00 00 00 00 00 00 00 00 00 00 00 00 00 00 00 00 00 00 00 00 00 00 00 00 00 00 00 00 00 00 00 00 00 00 00 00 00 00 00 00 00 00 00 00 00 00 00 00 00 00 00 00 00 00 00 00 00 00 00 00 00 00
					39 01 00 00 00 00 14 BC 00 00 00 00 00 00 00 00 00 00 00 00 00 00 00 00 00 00 00
					39 01 00 00 00 00 0D BD 00 00 00 00 00 00 00 00 00 00 00 00
					];
				qcom,mdss-dsi-lp1-command-state = "dsi_hs_mode";
				qcom,mdss-dsi-nolp-command-state = "dsi_hs_mode";
				qcom,mdss-dsi-post-on-backlight-state = "dsi_hs_mode";
				qcom,mdss-dsi-on-command-state = "dsi_lp_mode";
				qcom,mdss-dsi-off-command-state = "dsi_hs_mode";
				qcom,mdss-dsi-normal-hbm-on-command-state = "dsi_hs_mode";
				qcom,mdss-dsi-aod-high-mode-command-state = "dsi_hs_mode";
				qcom,mdss-dsi-aod-low-mode-command-state = "dsi_hs_mode";
				qcom,mdss-dsi-timing-switch-command-state = "dsi_lp_mode";
				qcom,compression-mode = "dsc";
				qcom,mdss-dsc-slice-height = <20>;
				qcom,mdss-dsc-slice-width = <540>;
				qcom,mdss-dsc-slice-per-pkt = <2>;
				qcom,mdss-dsc-bit-per-component = <8>;
				qcom,mdss-dsc-bit-per-pixel = <8>;
				qcom,mdss-dsc-block-prediction-enable;
			};
		};
	};
};

&dsi_oplus19101boe_nt37800_1080_2340_cmd {
	qcom,panel-supply-entries = <&dsi_panel_pwr_supply>;
	qcom,mdss-dsi-bl-pmic-control-type = "bl_ctrl_dcs";
	qcom,mdss-dsi-bl-min-level = <1>;
	qcom,mdss-dsi-bl-max-level = <1023>;
	qcom,platform-te-gpio = <&tlmm 10 0>;
	qcom,platform-reset-gpio = <&pm8150l_gpios 3 0>;
	qcom,ulps-enabled;
	qcom,dsi-select-clocks = "mux_byte_clk0", "mux_pixel_clk0",
				"src_byte_clk0", "src_pixel_clk0",
				"shadow_byte_clk0", "shadow_pixel_clk0";
	qcom,dsi-select-clocks = "mux_byte_clk0", "mux_pixel_clk0";
	qcom,mdss-dsi-t-clk-post = <0x0E>;
	qcom,mdss-dsi-t-clk-pre = <0x35>;
	qcom,mdss-dsi-display-timings {
		timing@0{
			qcom,mdss-dsi-panel-phy-timings = [00 1D 07 07 23 22 07
				07 05 02 04 00 18 17];

			qcom,display-topology = <1 1 1>;
			qcom,default-topology-index = <0>;
		};
		timing@1{
			qcom,mdss-dsi-panel-phy-timings = [00 1D 07 07 23 22 07
				07 05 02 04 00 18 17];

			qcom,display-topology = <1 1 1>;
			qcom,default-topology-index = <0>;
		};
	};
};

&dsi_oplus19101boe_nt37800_1080_2340_cmd {
	qcom,platform-iris-reset-gpio = <&tlmm 84 0>;
	qcom,platform-analog-bypass-gpio = <&tlmm 123 0>;
	qcom,platform-analog-bypass-status-gpio = <&tlmm 124 0>;
	qcom,platform-iris-vdd-gpio = <&tlmm 110 0>;
};
